VERSION "edgeplant-can0"

NS_ :

BS_:

BU_: ECU

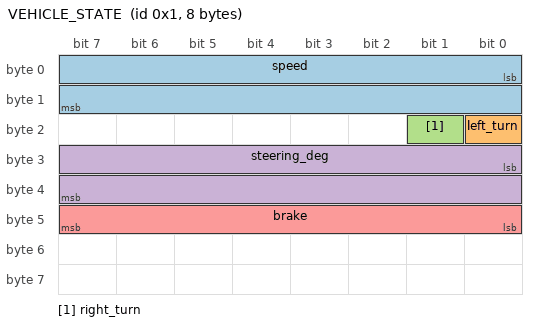
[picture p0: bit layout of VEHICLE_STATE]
BO_ 1 VEHICLE_STATE: 8 ECU
 SG_ speed : 0|16@1+ (0.01,0) [0|655.35] "km/h" ECU
 SG_ left_turn : 16|1@1+ (1,0) [0|1] "" ECU
 SG_ right_turn : 17|1@1+ (1,0) [0|1] "" ECU
 SG_ steering_deg : 24|16@1- (0.1,0) [-3276.8|3276.7] "deg" ECU
 SG_ brake : 40|8@1+ (0.4,0) [0|100] "%" ECU

BO_ 2 CONTROL_CMD: 8 ECU
 SG_ ControlCommand : 0|1@1+ (1,0) [0|1] "" ECU
 SG_ ControlValue : 8|16@1- (0.1,0) [-3276.8|3276.7] "" ECU
